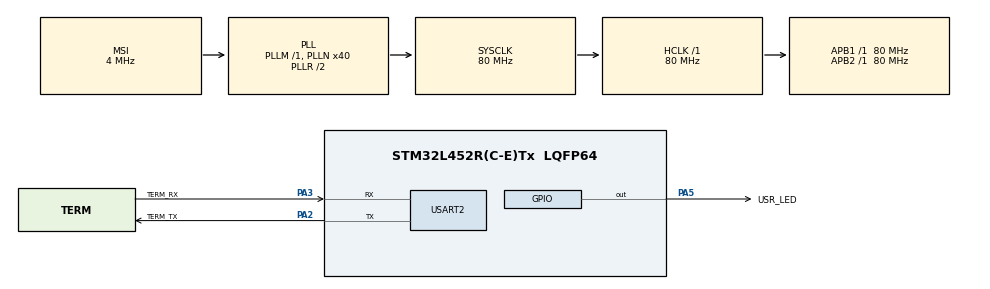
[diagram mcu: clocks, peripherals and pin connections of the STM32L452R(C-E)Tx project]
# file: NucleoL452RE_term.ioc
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Dma.Request0=USART2_RX
Dma.Request1=USART2_TX
Dma.USART2_RX.0.Direction=DMA_PERIPH_TO_MEMORY
Dma.USART2_RX.0.Instance=DMA1_Channel6
Dma.USART2_RX.0.MemDataAlignment=DMA_MDATAALIGN_BYTE
Dma.USART2_RX.0.MemInc=DMA_MINC_ENABLE
Dma.USART2_RX.0.Mode=DMA_NORMAL
Dma.USART2_RX.0.PeriphDataAlignment=DMA_PDATAALIGN_BYTE
Dma.USART2_RX.0.PeriphInc=DMA_PINC_DISABLE
Dma.USART2_RX.0.Priority=DMA_PRIORITY_LOW
Dma.USART2_TX.1.Direction=DMA_MEMORY_TO_PERIPH
Dma.USART2_TX.1.Instance=DMA1_Channel7
Dma.USART2_TX.1.MemDataAlignment=DMA_MDATAALIGN_BYTE
Dma.USART2_TX.1.MemInc=DMA_MINC_ENABLE
Dma.USART2_TX.1.Mode=DMA_NORMAL
Dma.USART2_TX.1.PeriphDataAlignment=DMA_PDATAALIGN_BYTE
Dma.USART2_TX.1.PeriphInc=DMA_PINC_DISABLE
Dma.USART2_TX.1.Priority=DMA_PRIORITY_LOW
Mcu.Family=STM32L4
Mcu.Name=STM32L452R(C-E)Tx
Mcu.Package=LQFP64
NVIC.DMA1_Channel6_IRQn=true\:0\:0\:false\:false\:true\:false
NVIC.DMA1_Channel7_IRQn=true\:0\:0\:false\:false\:true\:false
NVIC.PriorityGroup=NVIC_PRIORITYGROUP_4
NVIC.USART2_IRQn=true\:0\:0\:false\:false\:true\:true
PA2.GPIO_Label=TERM_TX
PA2.Mode=Asynchronous
PA2.Signal=USART2_TX
PA3.GPIO_Label=TERM_RX
PA3.Mode=Asynchronous
PA3.Signal=USART2_RX
PA5.GPIO_Label=USR_LED
PA5.Signal=GPIO_Output
ProjectManager.HeapSize=0x200
ProjectManager.StackSize=0x400
ProjectManager.TargetToolchain=TrueSTUDIO
RCC.AHBFreq_Value=80000000
RCC.APB1Freq_Value=80000000
RCC.APB1TimFreq_Value=80000000
RCC.APB2Freq_Value=80000000
RCC.APB2TimFreq_Value=80000000
RCC.CortexFreq_Value=80000000
RCC.HCLKFreq_Value=80000000
RCC.HSE_VALUE=8000000
RCC.HSI48_VALUE=48000000
RCC.HSI_VALUE=16000000
RCC.LSE_VALUE=32768
RCC.MSI_VALUE=4000000
RCC.PLLN=40
RCC.SYSCLKFreq_VALUE=80000000
RCC.SYSCLKSource=RCC_SYSCLKSOURCE_PLLCLK
RCC.VCOOutputFreq_Value=160000000
USART2.VirtualMode-Asynchronous=VM_ASYNC
board=custom

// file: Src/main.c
/**
  ******************************************************************************
  * @file           : main.c
  * @brief          : Main program body
  ******************************************************************************
  ** This notice applies to any and all portions of this file
  * that are not between comment pairs USER CODE BEGIN and
  * USER CODE END. Other portions of this file, whether
  * inserted by the user or by software development tools
  * are owned by their respective copyright owners.
  *
  * COPYRIGHT(c) 2018 STMicroelectronics
  *
  * Redistribution and use in source and binary forms, with or without modification,
  * are permitted provided that the following conditions are met:
  *   1. Redistributions of source code must retain the above copyright notice,
  *      this list of conditions and the following disclaimer.
  *   2. Redistributions in binary form must reproduce the above copyright notice,
  *      this list of conditions and the following disclaimer in the documentation
  *      and/or other materials provided with the distribution.
  *   3. Neither the name of STMicroelectronics nor the names of its contributors
  *      may be used to endorse or promote products derived from this software
  *      without specific prior written permission.
  *
  * THIS SOFTWARE IS PROVIDED BY THE COPYRIGHT HOLDERS AND CONTRIBUTORS "AS IS"
  * AND ANY EXPRESS OR IMPLIED WARRANTIES, INCLUDING, BUT NOT LIMITED TO, THE
  * IMPLIED WARRANTIES OF MERCHANTABILITY AND FITNESS FOR A PARTICULAR PURPOSE ARE
  * DISCLAIMED. IN NO EVENT SHALL THE COPYRIGHT HOLDER OR CONTRIBUTORS BE LIABLE
  * FOR ANY DIRECT, INDIRECT, INCIDENTAL, SPECIAL, EXEMPLARY, OR CONSEQUENTIAL
  * DAMAGES (INCLUDING, BUT NOT LIMITED TO, PROCUREMENT OF SUBSTITUTE GOODS OR
  * SERVICES; LOSS OF USE, DATA, OR PROFITS; OR BUSINESS INTERRUPTION) HOWEVER
  * CAUSED AND ON ANY THEORY OF LIABILITY, WHETHER IN CONTRACT, STRICT LIABILITY,
  * OR TORT (INCLUDING NEGLIGENCE OR OTHERWISE) ARISING IN ANY WAY OUT OF THE USE
  * OF THIS SOFTWARE, EVEN IF ADVISED OF THE POSSIBILITY OF SUCH DAMAGE.
  *
  ******************************************************************************
  */
#include "main.h"
#include "stm32l4xx_hal.h"

/* USER CODE BEGIN Includes */
#include "uart_term.h"

/* USER CODE END Includes */

UART_HandleTypeDef huart2;
DMA_HandleTypeDef hdma_usart2_rx;
DMA_HandleTypeDef hdma_usart2_tx;

//static uint8_t count = 0;
static char inBuff[15] = {0};
static int16_t inLen = 0;
static const uint8_t ref[11] = "OK READY";

/* USER CODE BEGIN PV */
/* Private variables ---------------------------------------------------------*/

/* USER CODE END PV */

void SystemClock_Config(void);
static void MX_GPIO_Init(void);
static void MX_DMA_Init(void);
static void MX_USART2_UART_Init(void);

#if (0)
static void term_Simple_Demo(void);
#endif

static uint16_t term_Parser(uint8_t* buffIn, uint8_t* buffRef, uint16_t buffLen);

/* USER CODE BEGIN PFP */
/* Private function prototypes -----------------------------------------------*/

/* USER CODE END PFP */

int main(void)
{

  /* MCU Configuration----------------------------------------------------------*/

  /* Reset of all peripherals, Initializes the Flash interface and the Systick. */
  HAL_Init();

  /* Configure the system clock */
  SystemClock_Config();

  /* Initialize all configured peripherals */
  MX_GPIO_Init();
  MX_DMA_Init();
  MX_USART2_UART_Init();

  /* USER CODE BEGIN 2 */

  InitTerm(115200);

  /* A first example */
#if (0)
  term_Simple_Demo();
#endif

  /* USER CODE END 2 */

  /* Infinite loop */
  /* USER CODE BEGIN WHILE */
  while (1)
  {

  	/* Parser demo */
  	ClearTerm();
  	UART_PRINT("%s\r\n", "Parser Demo");

  	UART_PRINT("Enter a string ");
		inLen = UART_GET(inBuff, 15);
		if (inLen == -1)
		{
			ERR_PRINT(101);
		}

		if (term_Parser((uint8_t *)inBuff, (uint8_t *)ref, 11) > 0)
		{
			/* Not equal */
			UART_PRINT("String enter %s is not equal to %s\r\n", inBuff, ref);
			HAL_GPIO_WritePin(USR_LED_GPIO_Port, USR_LED_Pin, GPIO_PIN_RESET);
		}

		if (term_Parser((uint8_t *)inBuff, (uint8_t *)ref, 11) == 0)
		{
			/* Equal */
			UART_PRINT("String enter %s is equal to %s\r\n", inBuff, ref);
			HAL_GPIO_WritePin(USR_LED_GPIO_Port, USR_LED_Pin, GPIO_PIN_SET);
		}

		HAL_Delay(2000);

  /* USER CODE END WHILE */

  }
}

void SystemClock_Config(void)
{

  RCC_OscInitTypeDef RCC_OscInitStruct;
  RCC_ClkInitTypeDef RCC_ClkInitStruct;
  RCC_PeriphCLKInitTypeDef PeriphClkInit;

  /* Initializes the CPU, AHB and APB busses clocks */
  RCC_OscInitStruct.OscillatorType = RCC_OSCILLATORTYPE_MSI;
  RCC_OscInitStruct.MSIState = RCC_MSI_ON;
  RCC_OscInitStruct.MSICalibrationValue = 0;
  RCC_OscInitStruct.MSIClockRange = RCC_MSIRANGE_6;
  RCC_OscInitStruct.PLL.PLLState = RCC_PLL_ON;
  RCC_OscInitStruct.PLL.PLLSource = RCC_PLLSOURCE_MSI;
  RCC_OscInitStruct.PLL.PLLM = 1;
  RCC_OscInitStruct.PLL.PLLN = 40;
  RCC_OscInitStruct.PLL.PLLP = RCC_PLLP_DIV7;
  RCC_OscInitStruct.PLL.PLLQ = RCC_PLLQ_DIV2;
  RCC_OscInitStruct.PLL.PLLR = RCC_PLLR_DIV2;
  if (HAL_RCC_OscConfig(&RCC_OscInitStruct) != HAL_OK)
  {
    _Error_Handler(__FILE__, __LINE__);
  }

  /* Initializes the CPU, AHB and APB busses clocks */
  RCC_ClkInitStruct.ClockType = RCC_CLOCKTYPE_HCLK|RCC_CLOCKTYPE_SYSCLK
                                |RCC_CLOCKTYPE_PCLK1|RCC_CLOCKTYPE_PCLK2;
  RCC_ClkInitStruct.SYSCLKSource = RCC_SYSCLKSOURCE_PLLCLK;
  RCC_ClkInitStruct.AHBCLKDivider = RCC_SYSCLK_DIV1;
  RCC_ClkInitStruct.APB1CLKDivider = RCC_HCLK_DIV1;
  RCC_ClkInitStruct.APB2CLKDivider = RCC_HCLK_DIV1;

  if (HAL_RCC_ClockConfig(&RCC_ClkInitStruct, FLASH_LATENCY_4) != HAL_OK)
  {
    _Error_Handler(__FILE__, __LINE__);
  }

  PeriphClkInit.PeriphClockSelection = RCC_PERIPHCLK_USART2;
  PeriphClkInit.Usart2ClockSelection = RCC_USART2CLKSOURCE_PCLK1;
  if (HAL_RCCEx_PeriphCLKConfig(&PeriphClkInit) != HAL_OK)
  {
    _Error_Handler(__FILE__, __LINE__);
  }

  /* Configure the main internal regulator output voltage*/
  if (HAL_PWREx_ControlVoltageScaling(PWR_REGULATOR_VOLTAGE_SCALE1) != HAL_OK)
  {
    _Error_Handler(__FILE__, __LINE__);
  }

  /* Configure the Systick interrupt time */
  HAL_SYSTICK_Config(HAL_RCC_GetHCLKFreq()/1000);

  /* Configure the Systick */
  HAL_SYSTICK_CLKSourceConfig(SYSTICK_CLKSOURCE_HCLK);

  /* SysTick_IRQn interrupt configuration */
  HAL_NVIC_SetPriority(SysTick_IRQn, 0, 0);
}

/* USART2 init function */
static void MX_USART2_UART_Init(void)
{

  huart2.Instance = USART2;
  huart2.Init.BaudRate = 115200;
  huart2.Init.WordLength = UART_WORDLENGTH_8B;
  huart2.Init.StopBits = UART_STOPBITS_1;
  huart2.Init.Parity = UART_PARITY_NONE;
  huart2.Init.Mode = UART_MODE_TX_RX;
  huart2.Init.HwFlowCtl = UART_HWCONTROL_NONE;
  huart2.Init.OverSampling = UART_OVERSAMPLING_16;
  huart2.Init.OneBitSampling = UART_ONE_BIT_SAMPLE_DISABLE;
  huart2.AdvancedInit.AdvFeatureInit = UART_ADVFEATURE_NO_INIT;
  if (HAL_UART_Init(&huart2) != HAL_OK)
  {
    _Error_Handler(__FILE__, __LINE__);
  }

}

static void MX_DMA_Init(void)
{
  /* DMA controller clock enable */
  __HAL_RCC_DMA1_CLK_ENABLE();

  /* DMA interrupt init */
  /* DMA1_Channel6_IRQn interrupt configuration */
  HAL_NVIC_SetPriority(DMA1_Channel6_IRQn, 0, 0);
  HAL_NVIC_EnableIRQ(DMA1_Channel6_IRQn);
  /* DMA1_Channel7_IRQn interrupt configuration */
  HAL_NVIC_SetPriority(DMA1_Channel7_IRQn, 0, 0);
  HAL_NVIC_EnableIRQ(DMA1_Channel7_IRQn);

}

/** Configure pins as
	* Analog
	* Input
	* Output
	* EVENT_OUT
	* EXTI
*/
static void MX_GPIO_Init(void)
{

  GPIO_InitTypeDef GPIO_InitStruct;

  /* GPIO Ports Clock Enable */
  __HAL_RCC_GPIOA_CLK_ENABLE();

  /* Configure GPIO pin Output Level */
  HAL_GPIO_WritePin(USR_LED_GPIO_Port, USR_LED_Pin, GPIO_PIN_RESET);

  /* Configure GPIO pin : USR_LED_Pin */
  GPIO_InitStruct.Pin = USR_LED_Pin;
  GPIO_InitStruct.Mode = GPIO_MODE_OUTPUT_PP;
  GPIO_InitStruct.Pull = GPIO_NOPULL;
  GPIO_InitStruct.Speed = GPIO_SPEED_FREQ_LOW;
  HAL_GPIO_Init(USR_LED_GPIO_Port, &GPIO_InitStruct);

}

/* USER CODE BEGIN 4 */

#if (0)
static void term_Simple_Demo(void)
{

	/* A first example */
	for (uint8_t index = 0; index < 19; index++)
	{
		UART_PRINT("Count = %d and it's address is 0x%x\n\r", index, &index);
		HAL_Delay(1000);
	}

	/* A string */
	UART_PRINT("A String: %s\r\n", "Hello World");
	/* An half Word integer */
	UART_PRINT("A 16-bit integer: %d\r\n", (uint16_t)0xff12);
	/* An Word integer */
	UART_PRINT("A 32-bit integer: %lu\r\n", (uint32_t)0xff123345);
	/* A float */
	UART_PRINT("A float %.2f\r\n", 3.14f); // Eclipse GCC -u_printf_float with a big amount of memory waste
	/* Wait a delay */
	HAL_Delay(2000);

	ClearTerm();

	while (1)
	{
		UART_PRINT("Enter a string ");
		inLen = UART_GET(inBuff, 8);
		if (inLen == -1)
		{
			UART_PRINT("\r\n");
			ERR_PRINT(101);
		}

		UART_PRINT("\r\nYou Enter %s contains %d characters\r\n", inBuff, inLen);
		HAL_Delay(1000);
	}
}
#endif

/**
 	* @brief Compares two buffers.
 	* @param buffIn, buffRef: buffers to be compared.
 	* @param buffLen: buffer's length.
 	* @retval =0 : buffIn identical to buffRef
 	* 			  >0 : buffIn differs from buffRef
 	*/
static uint16_t term_Parser(uint8_t* buffIn, uint8_t* buffRef, uint16_t buffLen)
{
	while (buffLen--)
	{
		if ((*buffIn != *buffRef))
		{
			return buffLen;
		}
		buffIn++;
		buffRef++;
	}

	return 0;
}

/* USER CODE END 4 */

void _Error_Handler(char *file, int line)
{
  while(1)
  {
  }
}

/************************ (C) COPYRIGHT STMicroelectronics *****END OF FILE****/
